# PIC32MZ1064DAA169 device description
Architecture: MIPS; Family: PIC32MZDA; Series: PIC32MZ
Registers are 32-bit, read-write, no defined reset value unless marked. A register's access mark holds for its fields unless they carry their own. Offsets are from the block's base; [hi:lo] are bit positions; {n}, {i} and the like mark numbered series; 'fields as' and 'values as' point back to an identical list.

## CMP
Instances: CMP 0x1f84c000 in periph_pb3_std
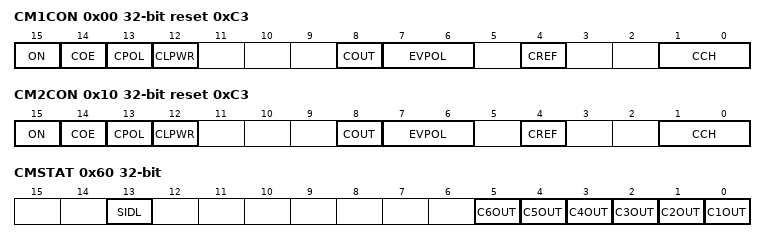
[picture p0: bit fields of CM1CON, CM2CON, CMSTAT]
0x00 CM1CON reset 0xC3 — Comparator Control Register
  [15] ON — Comparator ON bit
    1=Module is enabled. Setting this bit does not affect the other bits in this register; 0=Module is disabled and does not consume current. Clearing this bit does not affect the other bits in this register
  [14] COE — Comparator Output Enable bit
    1=Comparator output is driven on the output CxOUT pin; 0=Comparator output is not driven on the output CxOUT pin
  [13] CPOL — Comparator Output Inversion bit
    1=Output is inverted; 0=Output is not inverted
  [12] CLPWR
  [8] COUT — Comparator Output bit
    1=Output of the Comparator is a 1; 0=Output of the Comparator is a 0
  [7:6] EVPOL — Interrupt Event Polarity Select bits
    3=Comparator interrupt is generated on a low-to-high or high-to-low transition of the comparator output; 2=Comparator interrupt is generated on a high-to-low transition of the comparator output; 1=Comparator interrupt is generated on a low-to-high transition of the comparator output; 0=Comparator interrupt generation is disabled
  [4] CREF — Comparator Positive Input Configure bit
    1=Comparator non-inverting input is connected to the internal CVref; 0=Comparator non-inverting input is connected to the CxINA pin
  [1:0] CCH — Comparator Negative Input Select bits for Comparator
    3=Comparator inverting input is connected to the IVREF; 2=Comparator inverting input is connected to the CxIND pin; 1=Comparator inverting input is connected to the CxINC pin; 0=Comparator inverting input is connected to the CxINB pin
0x10 CM2CON reset 0xC3 — Comparator Control Register
  fields as CM1CON
0x60 CMSTAT — Comparator Status Register
  [13] SIDL — Stop in Idle Control bit
    1=All Comparator modules are disabled in Idle mode; 0=All Comparator modules continue to operate in the Idle mode
  [n-1] C{n}OUT (n=3..6)
  [1] C2OUT — Comparator Output bit
    1=Output of Comparator 2 is a 1; 0=Output of Comparator 2 is a 0
  [0] C1OUT — Comparator Output bit
    1=Output of Comparator 1 is a 1; 0=Output of Comparator 1 is a 0

## CTMU
Instances: CTMU 0x1f84c200 in periph_pb3_std
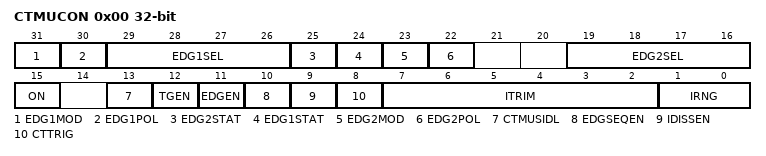
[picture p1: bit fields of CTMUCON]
0x00 CTMUCON — CTMU Control Register
  [31] EDG1MOD — Edge1 Edge Sampling Select bit
    1=Input is edge-sensitive; 0=Input is level-sensitive
  [30] EDG1POL — Edge 1 Polarity Select bit
    1=Edge1 programmed for a positive edge response; 0=Edge1 programmed for a negative edge response
  [29:26] EDG1SEL — Edge 1 Source Select bits
    14=C2OUT pin is selected; 13=C1OUT pin is selected; {v}=IC{v-6} Capture Event is selected (v=7..12); 6=OC4 Capture Event is selected; 5=OC3 Capture Event is selected; 4=OC2 Capture Event is selected; 3=CTED1 pin is selected; 2=CTED2 pin is selected; 1=OC1 Compare Event is selected; 0=Timer1 Event is selected
  [25] EDG2STAT — Edge2 Status bit
    1=Edge2 has occurred; 0=Edge2 has not occurred
  [24] EDG1STAT — Edge1 Status bit
    1=Edge1 has occurred; 0=Edge1 has not occurred
  [23] EDG2MOD — Edge2 Edge Sampling Select bit
    1=Input is edge-sensitive; 0=Input is level-sensitive
  [22] EDG2POL — Edge 2 Polarity Select bit
    1=Edge2 programmed for a positive edge response; 0=Edge2 programmed for a negative edge response
  [19:16] EDG2SEL — Edge 2 Source Select bits
    56=C2OUT pin is selected; 52=C1OUT pin is selected; 48=PBCLK3; 44=IC5 Capture Event is selected; 40=IC4 Capture Event is selected; 36=IC3 Capture Event is selected; 32=IC2 Capture Event is selected; 28=IC1 Capture Event is selected; 24=OC4 Capture Event is selected; 20=OC3 Capture Event is selected; 16=OC2 Capture Event is selected; 12=CTED1 pin is selected; 8=CTED2 pin is selected; 4=OC1 Compare Event is selected; 0=Timer1 Event is selected
  [15] ON — ON Enable bit
    1=Module is enabled; 0=Module is disabled
  [13] CTMUSIDL — Stop-in-Idle Mode bit
    1=Discontinue module operation when device enters Idle mode; 0=Continue module operation in Idle mode
  [12] TGEN — Time Generation Enable bit
    1=Enables edge delay generation; 0=Disables edge delay generation
  [11] EDGEN — Edge Enable bit
    1=Edges are not blocked; 0=Edges are blocked
  [10] EDGSEQEN — Edge Sequence Enable bit
    1=Edge1 must occur before Edge2 can occur; 0=No edge sequence is needed
  [9] IDISSEN — Analog Current Source Control bit
    1=Analog current source output is grounded; 0=Analog current source output is not grounded
  [8] CTTRIG — Trigger Control bit
    1=Trigger output is enabled; 0=Trigger output is disabled
  [7:2] ITRIM — Current Source Trim bits
    31=Maximum positive change from nominal current; 1=Minimum positive change from nominal current; 0=Nominal current output specified by IRNG; 63=Minimum negative change from nominal current; 33=Maximum negative change from nominal current
  [1:0] IRNG — Current Range Select bits
    3=100 times base current; 2=10 times base current; 1=Base current level; 0=1000 times base current(4)

## Notices in the file
Copyright (c) 2017 Microchip Technology Inc.
SPDX-License-Identifier: Apache-2.0
Licensed under the Apache License, Version 2.0 (the "License");
you may not use this file except in compliance with the License.
You may obtain a copy of the License at
http://www.apache.org/licenses/LICENSE-2.0
Unless required by applicable law or agreed to in writing, software
distributed under the License is distributed on an "AS IS" BASIS,
WITHOUT WARRANTIES OR CONDITIONS OF ANY KIND, either express or implied.
See the License for the specific language governing permissions and
limitations under the License.
